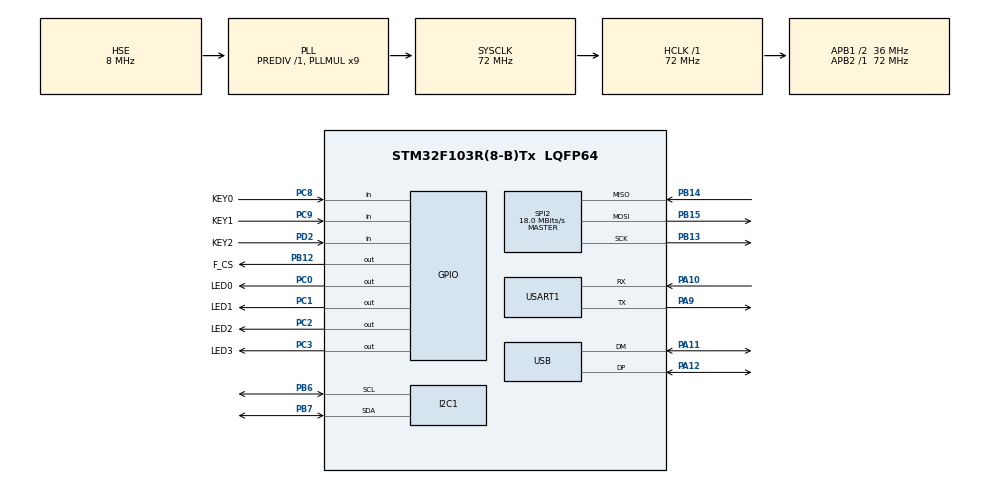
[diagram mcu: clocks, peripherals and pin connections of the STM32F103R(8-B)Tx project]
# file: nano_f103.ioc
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FREERTOS.Tasks01=defaultTask,24,150,StartDefaultTask,Default,NULL,Dynamic,NULL,NULL
FREERTOS.configTOTAL_HEAP_SIZE=10240
FREERTOS.configUSE_NEWLIB_REENTRANT=1
I2C1.AddressingMode=I2C_ADDRESSINGMODE_7BIT
Mcu.Family=STM32F1
Mcu.Name=STM32F103R(8-B)Tx
Mcu.Package=LQFP64
NVIC.PriorityGroup=NVIC_PRIORITYGROUP_4
NVIC.TIM3_IRQn=true\:15\:0\:false\:false\:true\:false\:false\:true\:true
NVIC.TimeBase=TIM3_IRQn
NVIC.TimeBaseIP=TIM3
NVIC.USART1_IRQn=true\:5\:0\:false\:false\:true\:true\:true\:true\:true
NVIC.USB_HP_CAN1_TX_IRQn=true\:5\:0\:false\:false\:true\:true\:true\:true\:true
NVIC.USB_LP_CAN1_RX0_IRQn=true\:5\:0\:false\:false\:true\:true\:true\:true\:true
PA10.Mode=Asynchronous
PA10.Signal=USART1_RX
PA11.Mode=Device
PA11.Signal=USB_DM
PA12.Mode=Device
PA12.Signal=USB_DP
PA13.Mode=Serial_Wire
PA13.Signal=SYS_JTMS-SWDIO
PA14.Mode=Serial_Wire
PA14.Signal=SYS_JTCK-SWCLK
PA9.Mode=Asynchronous
PA9.Signal=USART1_TX
PB12.GPIO_Label=F_CS
PB12.Signal=GPIO_Output
PB13.Mode=Full_Duplex_Master
PB13.Signal=SPI2_SCK
PB14.Mode=Full_Duplex_Master
PB14.Signal=SPI2_MISO
PB15.Mode=Full_Duplex_Master
PB15.Signal=SPI2_MOSI
PB6.Mode=I2C
PB6.Signal=I2C1_SCL
PB7.Mode=I2C
PB7.Signal=I2C1_SDA
PC0.GPIO_Label=LED0
PC0.GPIO_Speed=GPIO_SPEED_FREQ_HIGH
PC0.PinState=GPIO_PIN_SET
PC0.Signal=GPIO_Output
PC1.GPIO_Label=LED1
PC1.GPIO_Speed=GPIO_SPEED_FREQ_HIGH
PC1.PinState=GPIO_PIN_SET
PC1.Signal=GPIO_Output
PC14-OSC32_IN.Mode=LSE-External-Oscillator
PC14-OSC32_IN.Signal=RCC_OSC32_IN
PC15-OSC32_OUT.Mode=LSE-External-Oscillator
PC15-OSC32_OUT.Signal=RCC_OSC32_OUT
PC2.GPIO_Label=LED2
PC2.GPIO_Speed=GPIO_SPEED_FREQ_HIGH
PC2.PinState=GPIO_PIN_SET
PC2.Signal=GPIO_Output
PC3.GPIO_Label=LED3
PC3.GPIO_Speed=GPIO_SPEED_FREQ_HIGH
PC3.PinState=GPIO_PIN_SET
PC3.Signal=GPIO_Output
PC8.GPIO_Label=KEY0
PC8.GPIO_Mode=GPIO_MODE_INPUT
PC8.GPIO_PuPd=GPIO_PULLUP
PC8.Signal=GPIO_Input
PC9.GPIO_Label=KEY1
PC9.GPIO_Mode=GPIO_MODE_INPUT
PC9.GPIO_PuPd=GPIO_PULLUP
PC9.Signal=GPIO_Input
PD0-OSC_IN.Mode=HSE-External-Oscillator
PD0-OSC_IN.Signal=RCC_OSC_IN
PD1-OSC_OUT.Mode=HSE-External-Oscillator
PD1-OSC_OUT.Signal=RCC_OSC_OUT
PD2.GPIO_Label=KEY2
PD2.GPIO_PuPd=GPIO_PULLUP
PD2.Signal=GPIO_Input
ProjectManager.HeapSize=0x400
ProjectManager.StackSize=0x800
ProjectManager.TargetToolchain=CMake
RCC.AHBFreq_Value=72000000
RCC.APB1CLKDivider=RCC_HCLK_DIV2
RCC.APB1Freq_Value=36000000
RCC.APB1TimFreq_Value=72000000
RCC.APB2Freq_Value=72000000
RCC.APB2TimFreq_Value=72000000
RCC.HCLKFreq_Value=72000000
RCC.PLLMUL=RCC_PLL_MUL9
RCC.PLLSourceVirtual=RCC_PLLSOURCE_HSE
RCC.RTCClockSelection=RCC_RTCCLKSOURCE_LSE
RCC.SYSCLKFreq_VALUE=72000000
RCC.SYSCLKSource=RCC_SYSCLKSOURCE_PLLCLK
RCC.USBFreq_Value=48000000
RCC.USBPrescaler=RCC_USBCLKSOURCE_PLL_DIV1_5
RTC.Format=RTC_FORMAT_BCD
SPI2.CalculateBaudRate=18.0 MBits/s
SPI2.Direction=SPI_DIRECTION_2LINES
SPI2.Mode=SPI_MODE_MASTER
SPI2.VirtualType=VM_MASTER
USART1.VirtualMode=VM_ASYNC
USB.low_power_enable=DISABLE
USB.lpm_enable=DISABLE
USB_DEVICE.CLASS_NAME_FS=CDC
USB_DEVICE.VirtualMode=Cdc
USB_DEVICE.VirtualModeFS=Cdc_FS
VP_FREERTOS_VS_CMSIS_V2.Mode=CMSIS_V2
VP_RTC_VS_RTC_Activate.Mode=RTC_Enabled
VP_SYS_VS_tim3.Mode=TIM3
VP_TIM4_VS_ClockSourceINT.Mode=Internal
VP_USB_DEVICE_VS_USB_DEVICE_CDC_FS.Mode=CDC_FS
board=custom

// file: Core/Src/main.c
/* USER CODE BEGIN Header */
/**
  ******************************************************************************
  * @file           : main.c
  * @brief          : Main program body
  ******************************************************************************
  * @attention
  *
  * Copyright (c) 2024 STMicroelectronics.
  * All rights reserved.
  *
  * This software is licensed under terms that can be found in the LICENSE file
  * in the root directory of this software component.
  * If no LICENSE file comes with this software, it is provided AS-IS.
  *
  ******************************************************************************
  */
/* USER CODE END Header */
#include "main.h"
#include "cmsis_os.h"
#include "usb_device.h"

I2C_HandleTypeDef hi2c1;

RTC_HandleTypeDef hrtc;

SPI_HandleTypeDef hspi2;

TIM_HandleTypeDef htim4;

UART_HandleTypeDef huart1;

/* Definitions for defaultTask */
osThreadId_t defaultTaskHandle;
const osThreadAttr_t defaultTask_attributes = {
  .name = "defaultTask",
  .stack_size = 150 * 4,
  .priority = (osPriority_t) osPriorityNormal,
};

void SystemClock_Config(void);
static void MX_GPIO_Init(void);
static void MX_I2C1_Init(void);
static void MX_SPI2_Init(void);
static void MX_TIM4_Init(void);
static void MX_USART1_UART_Init(void);
static void MX_RTC_Init(void);
void StartDefaultTask(void *argument);

/* USER CODE BEGIN PFP */
extern void app(void);
extern void board_init(void);
/* USER CODE END PFP */

int main(void)
{

  /* MCU Configuration--------------------------------------------------------*/

  /* Reset of all peripherals, Initializes the Flash interface and the Systick. */
  HAL_Init();

  /* Configure the system clock */
  SystemClock_Config();

  /* Initialize all configured peripherals */
  MX_GPIO_Init();
  MX_I2C1_Init();
  MX_SPI2_Init();
  MX_TIM4_Init();
  MX_USART1_UART_Init();
  MX_RTC_Init();

  /* Init scheduler */
  osKernelInitialize();

  /* USER CODE BEGIN RTOS_MUTEX */
  /* add mutexes, ... */
  board_init();
  /* USER CODE END RTOS_MUTEX */

  /* Create the thread(s) */
  /* creation of defaultTask */
  defaultTaskHandle = osThreadNew(StartDefaultTask, NULL, &defaultTask_attributes);

  /* Start scheduler */
  osKernelStart();

  /* We should never get here as control is now taken by the scheduler */

  /* Infinite loop */
  while (1)
  {

  }
}

void SystemClock_Config(void)
{
  RCC_OscInitTypeDef RCC_OscInitStruct = {0};
  RCC_ClkInitTypeDef RCC_ClkInitStruct = {0};
  RCC_PeriphCLKInitTypeDef PeriphClkInit = {0};

  /** Initializes the RCC Oscillators according to the specified parameters
  * in the RCC_OscInitTypeDef structure.
  */
  RCC_OscInitStruct.OscillatorType = RCC_OSCILLATORTYPE_HSE|RCC_OSCILLATORTYPE_LSE;
  RCC_OscInitStruct.HSEState = RCC_HSE_ON;
  RCC_OscInitStruct.HSEPredivValue = RCC_HSE_PREDIV_DIV1;
  RCC_OscInitStruct.LSEState = RCC_LSE_ON;
  RCC_OscInitStruct.HSIState = RCC_HSI_ON;
  RCC_OscInitStruct.PLL.PLLState = RCC_PLL_ON;
  RCC_OscInitStruct.PLL.PLLSource = RCC_PLLSOURCE_HSE;
  RCC_OscInitStruct.PLL.PLLMUL = RCC_PLL_MUL9;
  if (HAL_RCC_OscConfig(&RCC_OscInitStruct) != HAL_OK)
  {
    Error_Handler();
  }

  /** Initializes the CPU, AHB and APB buses clocks
  */
  RCC_ClkInitStruct.ClockType = RCC_CLOCKTYPE_HCLK|RCC_CLOCKTYPE_SYSCLK
                              |RCC_CLOCKTYPE_PCLK1|RCC_CLOCKTYPE_PCLK2;
  RCC_ClkInitStruct.SYSCLKSource = RCC_SYSCLKSOURCE_PLLCLK;
  RCC_ClkInitStruct.AHBCLKDivider = RCC_SYSCLK_DIV1;
  RCC_ClkInitStruct.APB1CLKDivider = RCC_HCLK_DIV2;
  RCC_ClkInitStruct.APB2CLKDivider = RCC_HCLK_DIV1;

  if (HAL_RCC_ClockConfig(&RCC_ClkInitStruct, FLASH_LATENCY_2) != HAL_OK)
  {
    Error_Handler();
  }
  PeriphClkInit.PeriphClockSelection = RCC_PERIPHCLK_RTC|RCC_PERIPHCLK_USB;
  PeriphClkInit.RTCClockSelection = RCC_RTCCLKSOURCE_LSE;
  PeriphClkInit.UsbClockSelection = RCC_USBCLKSOURCE_PLL_DIV1_5;
  if (HAL_RCCEx_PeriphCLKConfig(&PeriphClkInit) != HAL_OK)
  {
    Error_Handler();
  }
}

static void MX_I2C1_Init(void)
{

  hi2c1.Instance = I2C1;
  hi2c1.Init.ClockSpeed = 100000;
  hi2c1.Init.DutyCycle = I2C_DUTYCYCLE_2;
  hi2c1.Init.OwnAddress1 = 0;
  hi2c1.Init.AddressingMode = I2C_ADDRESSINGMODE_7BIT;
  hi2c1.Init.DualAddressMode = I2C_DUALADDRESS_DISABLE;
  hi2c1.Init.OwnAddress2 = 0;
  hi2c1.Init.GeneralCallMode = I2C_GENERALCALL_DISABLE;
  hi2c1.Init.NoStretchMode = I2C_NOSTRETCH_DISABLE;
  if (HAL_I2C_Init(&hi2c1) != HAL_OK)
  {
    Error_Handler();
  }

}

static void MX_RTC_Init(void)
{

  /** Initialize RTC Only
  */
  hrtc.Instance = RTC;
  hrtc.Init.AsynchPrediv = RTC_AUTO_1_SECOND;
  hrtc.Init.OutPut = RTC_OUTPUTSOURCE_ALARM;
  if (HAL_RTC_Init(&hrtc) != HAL_OK)
  {
    Error_Handler();
  }

}

static void MX_SPI2_Init(void)
{

  /* SPI2 parameter configuration*/
  hspi2.Instance = SPI2;
  hspi2.Init.Mode = SPI_MODE_MASTER;
  hspi2.Init.Direction = SPI_DIRECTION_2LINES;
  hspi2.Init.DataSize = SPI_DATASIZE_8BIT;
  hspi2.Init.CLKPolarity = SPI_POLARITY_LOW;
  hspi2.Init.CLKPhase = SPI_PHASE_1EDGE;
  hspi2.Init.NSS = SPI_NSS_SOFT;
  hspi2.Init.BaudRatePrescaler = SPI_BAUDRATEPRESCALER_2;
  hspi2.Init.FirstBit = SPI_FIRSTBIT_MSB;
  hspi2.Init.TIMode = SPI_TIMODE_DISABLE;
  hspi2.Init.CRCCalculation = SPI_CRCCALCULATION_DISABLE;
  hspi2.Init.CRCPolynomial = 10;
  if (HAL_SPI_Init(&hspi2) != HAL_OK)
  {
    Error_Handler();
  }

}

static void MX_TIM4_Init(void)
{

  TIM_ClockConfigTypeDef sClockSourceConfig = {0};
  TIM_MasterConfigTypeDef sMasterConfig = {0};

  htim4.Instance = TIM4;
  htim4.Init.Prescaler = 0;
  htim4.Init.CounterMode = TIM_COUNTERMODE_UP;
  htim4.Init.Period = 65535;
  htim4.Init.ClockDivision = TIM_CLOCKDIVISION_DIV1;
  htim4.Init.AutoReloadPreload = TIM_AUTORELOAD_PRELOAD_DISABLE;
  if (HAL_TIM_Base_Init(&htim4) != HAL_OK)
  {
    Error_Handler();
  }
  sClockSourceConfig.ClockSource = TIM_CLOCKSOURCE_INTERNAL;
  if (HAL_TIM_ConfigClockSource(&htim4, &sClockSourceConfig) != HAL_OK)
  {
    Error_Handler();
  }
  sMasterConfig.MasterOutputTrigger = TIM_TRGO_RESET;
  sMasterConfig.MasterSlaveMode = TIM_MASTERSLAVEMODE_DISABLE;
  if (HAL_TIMEx_MasterConfigSynchronization(&htim4, &sMasterConfig) != HAL_OK)
  {
    Error_Handler();
  }

}

static void MX_USART1_UART_Init(void)
{

  huart1.Instance = USART1;
  huart1.Init.BaudRate = 115200;
  huart1.Init.WordLength = UART_WORDLENGTH_8B;
  huart1.Init.StopBits = UART_STOPBITS_1;
  huart1.Init.Parity = UART_PARITY_NONE;
  huart1.Init.Mode = UART_MODE_TX_RX;
  huart1.Init.HwFlowCtl = UART_HWCONTROL_NONE;
  huart1.Init.OverSampling = UART_OVERSAMPLING_16;
  if (HAL_UART_Init(&huart1) != HAL_OK)
  {
    Error_Handler();
  }

}

static void MX_GPIO_Init(void)
{
  GPIO_InitTypeDef GPIO_InitStruct = {0};

  /* GPIO Ports Clock Enable */
  __HAL_RCC_GPIOC_CLK_ENABLE();
  __HAL_RCC_GPIOD_CLK_ENABLE();
  __HAL_RCC_GPIOB_CLK_ENABLE();
  __HAL_RCC_GPIOA_CLK_ENABLE();

  /*Configure GPIO pin Output Level */
  HAL_GPIO_WritePin(GPIOC, LED0_Pin|LED1_Pin|LED2_Pin|LED3_Pin, GPIO_PIN_SET);

  /*Configure GPIO pin Output Level */
  HAL_GPIO_WritePin(F_CS_GPIO_Port, F_CS_Pin, GPIO_PIN_RESET);

  /*Configure GPIO pins : LED0_Pin LED1_Pin LED2_Pin LED3_Pin */
  GPIO_InitStruct.Pin = LED0_Pin|LED1_Pin|LED2_Pin|LED3_Pin;
  GPIO_InitStruct.Mode = GPIO_MODE_OUTPUT_PP;
  GPIO_InitStruct.Pull = GPIO_NOPULL;
  GPIO_InitStruct.Speed = GPIO_SPEED_FREQ_HIGH;
  HAL_GPIO_Init(GPIOC, &GPIO_InitStruct);

  /*Configure GPIO pin : F_CS_Pin */
  GPIO_InitStruct.Pin = F_CS_Pin;
  GPIO_InitStruct.Mode = GPIO_MODE_OUTPUT_PP;
  GPIO_InitStruct.Pull = GPIO_NOPULL;
  GPIO_InitStruct.Speed = GPIO_SPEED_FREQ_LOW;
  HAL_GPIO_Init(F_CS_GPIO_Port, &GPIO_InitStruct);

  /*Configure GPIO pins : KEY0_Pin KEY1_Pin */
  GPIO_InitStruct.Pin = KEY0_Pin|KEY1_Pin;
  GPIO_InitStruct.Mode = GPIO_MODE_INPUT;
  GPIO_InitStruct.Pull = GPIO_PULLUP;
  HAL_GPIO_Init(GPIOC, &GPIO_InitStruct);

  /*Configure GPIO pin : KEY2_Pin */
  GPIO_InitStruct.Pin = KEY2_Pin;
  GPIO_InitStruct.Mode = GPIO_MODE_INPUT;
  GPIO_InitStruct.Pull = GPIO_PULLUP;
  HAL_GPIO_Init(KEY2_GPIO_Port, &GPIO_InitStruct);

}

void StartDefaultTask(void *argument)
{
  /* init code for USB_DEVICE */
  MX_USB_DEVICE_Init();
  /* USER CODE BEGIN 5 */
  /* Infinite loop */
  app();
  for(;;)
  {
    osDelay(1);
  }
  /* USER CODE END 5 */
}

void HAL_TIM_PeriodElapsedCallback(TIM_HandleTypeDef *htim)
{
  if (htim->Instance == TIM3) {
    HAL_IncTick();
  }
}

void Error_Handler(void)
{
  __disable_irq();
  while (1)
  {
  }
}
